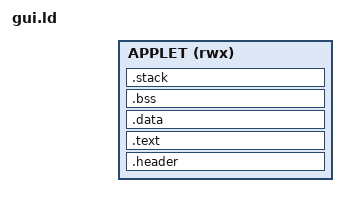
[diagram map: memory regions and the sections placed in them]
/*
    applet.ld - generated by tools/applet_ld_wizard.py

    Profile: desktop
    Desktop slot: 1
    SDRAM base: 0xD0000000
    Usable SDRAM: 6 MB / 0x600000
    RAM disk reserve: 128 KB / 0x20000
    RAM disk starts: 0xD05E0000
    Reserved before applet: 5760 KB / 0x5A0000
    Applet origin: 0xD05A0000
    Applet allowance: 128 KB / 0x20000
*/

/* Base and limits */
_offset            = 0xD0000000;
_maxramavail       = 0x600000;
_stack_size        = 0x2000;
_ramdisk_size      = 0x20000;

/* Wizard choices, all in bytes. Do not multiply these by 1024 again. :) */
_profile_is_desktop = 1;
_desktop_slot       = 1;
_requested_app_size = 0x20000;
_largest_modfile    = 0x5A0000;
_largest_resource   = 0x0;
_applet_ram_top     = _maxramavail - _ramdisk_size;
_ramdisk_startram   = _applet_ram_top;

/* Desktop apps are parked near the end of applet SDRAM, below the RAM disk.
   Games start after the reserved music/resource area. */
_desktop_startram = ((_applet_ram_top - (_requested_app_size * (_desktop_slot + 1))) & ~31);
_game_startram    = ((_largest_modfile + _largest_resource + 31) & ~31);
_startram         = _profile_is_desktop ? _desktop_startram : _game_startram;

_applet_origin    = _offset + _startram;
_applet_length    = _profile_is_desktop ? _requested_app_size : (_applet_ram_top - _startram);
_sdram_end        = _offset + _maxramavail;
_ramdisk_origin   = _offset + _ramdisk_startram;

ASSERT(_startram < _applet_ram_top, "Reserved space exceeds applet SDRAM!")
ASSERT(_applet_length > _stack_size, "No RAM left for applet after stack reserve!")
ASSERT((_startram & 31) == 0, "Applet start must be 32-byte aligned!")

/* SIDBOX API table location. Must match the core applets linker layout. */
_api_count = 512;
_api_size  = (8 * _api_count);
_api_location = 0x20020000 - _api_size;

MEMORY {
    APPLET (rwx) : ORIGIN = (_offset + _startram), LENGTH = _applet_length
}

_appstart = ORIGIN(APPLET);
PROVIDE(__app_start = _appstart);

SECTIONS {
    PROVIDE(__sidbox_api_location = _api_location);

    . = _appstart;

    /* Header = 16 bytes total: magic(8) + loadAddr(4) + memLen(4) */
    .header _appstart : {
        . = ALIGN(4);
        KEEP(*(.header))
        . = ALIGN(4);
        LONG(_appstart);
        LONG(__stack_end__ - _appstart);
    } > APPLET

    .text (_appstart + 0x10) : {
        . = ALIGN(4);
        KEEP(*(.text.applet_entry))
        *(.text*)
        *(.rodata*)
    } > APPLET

    .data : {
        . = ALIGN(4);
        *(.data*)
    } > APPLET

    .bss (NOLOAD) : {
        . = ALIGN(4);
        __bss_start__ = .;
        *(.bss*)
        *(COMMON)
        . = ALIGN(4);
        __bss_end__ = .;
    } > APPLET

    .stack (NOLOAD) : {
        . = ALIGN(8);
        __stack_start__ = .;
        . = . + _stack_size;
        . = ALIGN(8);
        __stack_end__ = .;
    } > APPLET

    PROVIDE(__app_end_clear = __stack_end__);
    PROVIDE(_estack = __stack_end__);

    _end = .;
    __app_end = .;

    ASSERT(__stack_end__ <= (_appstart + LENGTH(APPLET)), "Applet image exceeds selected app size!")
    ASSERT(__stack_end__ <= _sdram_end, "Applet image exceeds SDRAM end!")
    ASSERT(__stack_end__ <= _ramdisk_origin, "Applet image overlaps RAM disk!")
}
